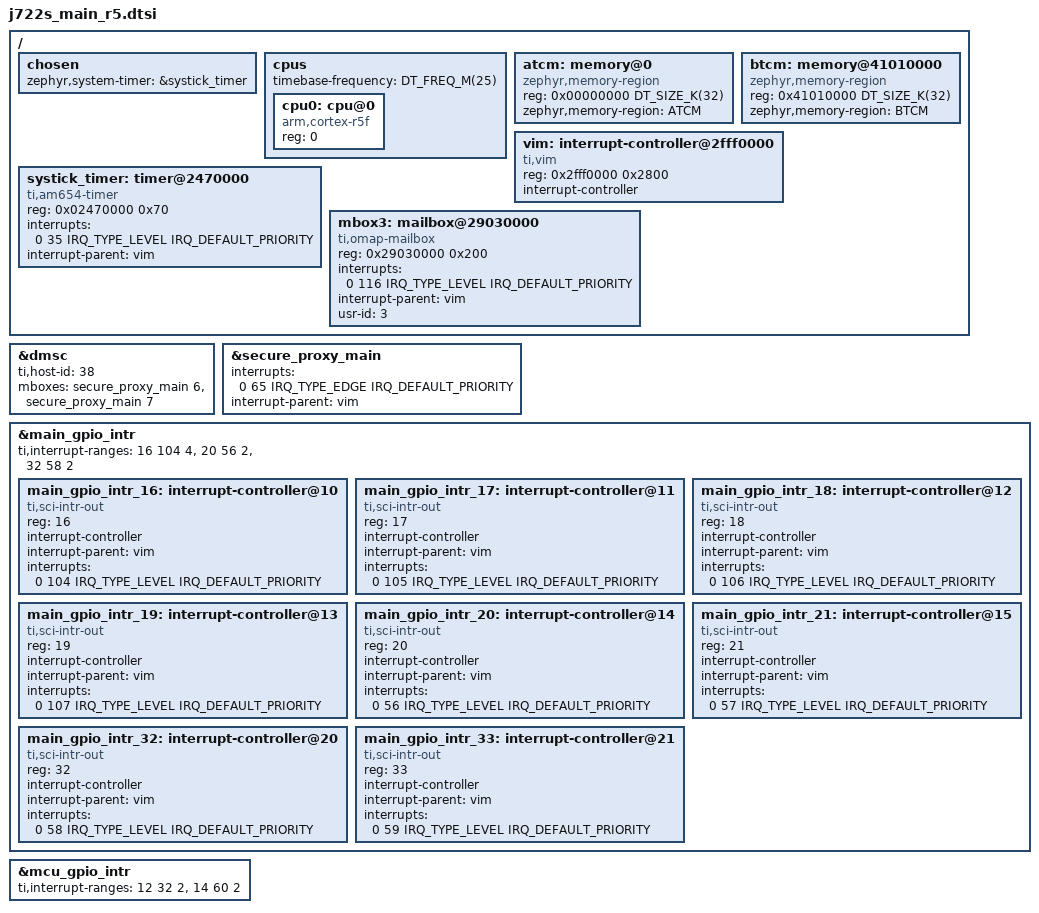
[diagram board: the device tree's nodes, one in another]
/*
 * Copyright (c) 2024 Texas Instruments Incorporated
 *	Andrew Davis <afd@ti.com>
 *
 * SPDX-License-Identifier: Apache-2.0
 */

#include <mem.h>
#include <freq.h>
#include <arm/armv7-r.dtsi>
#include <zephyr/dt-bindings/interrupt-controller/ti-vim.h>

#include "j722s_mcu.dtsi"
#include "j722s_main.dtsi"

/ {
	#address-cells = <1>;
	#size-cells = <1>;

	chosen {
		zephyr,system-timer = &systick_timer;
	};

	cpus {
		#address-cells = <1>;
		#size-cells = <0>;
		timebase-frequency = <DT_FREQ_M(25)>;

		cpu0: cpu@0 {
			device_type = "cpu";
			compatible = "arm,cortex-r5f";
			reg = <0>;
		};
	};

	atcm: memory@0 {
		device_type = "memory";
		compatible = "zephyr,memory-region", "mmio-sram";
		reg = <0x00000000 DT_SIZE_K(32)>;
		zephyr,memory-region = "ATCM";
	};

	btcm: memory@41010000 {
		device_type = "memory";
		compatible = "zephyr,memory-region", "mmio-sram";
		reg = <0x41010000 DT_SIZE_K(32)>;
		zephyr,memory-region = "BTCM";
	};

	vim: interrupt-controller@2fff0000 {
		#address-cells = <1>;
		compatible = "ti,vim";
		reg = <0x2fff0000 0x2800>;
		interrupt-controller;
		#interrupt-cells = <4>; /* {IRQ/FIQ, IRQ_NUM, IRQ_TYPE, IRQ_PRIO} */
		status = "okay";
	};

	systick_timer: timer@2470000 {
		compatible = "ti,am654-timer";
		reg = <0x02470000 0x70>;
		interrupts = <0 35 IRQ_TYPE_LEVEL IRQ_DEFAULT_PRIORITY>;
		interrupt-parent = <&vim>;
		status = "okay";
	};

	mbox3: mailbox@29030000 {
		compatible = "ti,omap-mailbox";
		reg = <0x29030000 0x200>;
		interrupts = <0 116 IRQ_TYPE_LEVEL IRQ_DEFAULT_PRIORITY>;
		interrupt-parent = <&vim>;
		usr-id = <3>;
		#mbox-cells = <1>;
		status = "okay";
	};
};

/* MAIN_0_R5_1 (non-secure): host 38, secure-proxy threads 6/7 */
&dmsc {
	ti,host-id = <38>;
	mboxes = <&secure_proxy_main 6>, <&secure_proxy_main 7>;
};

&secure_proxy_main {
	interrupt-names = "rx_6";
	interrupts = <0 65 IRQ_TYPE_EDGE IRQ_DEFAULT_PRIORITY>;
	interrupt-parent = <&vim>;
};

/*
 * MAIN GPIOMUX INTROUTER outputs wired to MAIN R5F VIM:
 *   out 16..19 -> VIM 104..107
 *   out 20..21 -> VIM 56..57
 *   out 32..33 -> VIM 58..59
 *
 * Each output is a ti,sci-intr-out child so peripherals can use
 * interrupt-parent = <&main_gpio_intr_N> with IR input in interrupts.
 * NUM_2ND_LEVEL_AGGREGATORS is capped at 8, matching these eight outputs.
 */
&main_gpio_intr {
	ti,interrupt-ranges = <16 104 4>,
			      <20 56 2>,
			      <32 58 2>;

	main_gpio_intr_16: interrupt-controller@10 {
		compatible = "ti,sci-intr-out";
		reg = <16>;
		interrupt-controller;
		#interrupt-cells = <2>;
		interrupt-parent = <&vim>;
		interrupts = <0 104 IRQ_TYPE_LEVEL IRQ_DEFAULT_PRIORITY>;
	};

	main_gpio_intr_17: interrupt-controller@11 {
		compatible = "ti,sci-intr-out";
		reg = <17>;
		interrupt-controller;
		#interrupt-cells = <2>;
		interrupt-parent = <&vim>;
		interrupts = <0 105 IRQ_TYPE_LEVEL IRQ_DEFAULT_PRIORITY>;
	};

	main_gpio_intr_18: interrupt-controller@12 {
		compatible = "ti,sci-intr-out";
		reg = <18>;
		interrupt-controller;
		#interrupt-cells = <2>;
		interrupt-parent = <&vim>;
		interrupts = <0 106 IRQ_TYPE_LEVEL IRQ_DEFAULT_PRIORITY>;
	};

	main_gpio_intr_19: interrupt-controller@13 {
		compatible = "ti,sci-intr-out";
		reg = <19>;
		interrupt-controller;
		#interrupt-cells = <2>;
		interrupt-parent = <&vim>;
		interrupts = <0 107 IRQ_TYPE_LEVEL IRQ_DEFAULT_PRIORITY>;
	};

	main_gpio_intr_20: interrupt-controller@14 {
		compatible = "ti,sci-intr-out";
		reg = <20>;
		interrupt-controller;
		#interrupt-cells = <2>;
		interrupt-parent = <&vim>;
		interrupts = <0 56 IRQ_TYPE_LEVEL IRQ_DEFAULT_PRIORITY>;
	};

	main_gpio_intr_21: interrupt-controller@15 {
		compatible = "ti,sci-intr-out";
		reg = <21>;
		interrupt-controller;
		#interrupt-cells = <2>;
		interrupt-parent = <&vim>;
		interrupts = <0 57 IRQ_TYPE_LEVEL IRQ_DEFAULT_PRIORITY>;
	};

	main_gpio_intr_32: interrupt-controller@20 {
		compatible = "ti,sci-intr-out";
		reg = <32>;
		interrupt-controller;
		#interrupt-cells = <2>;
		interrupt-parent = <&vim>;
		interrupts = <0 58 IRQ_TYPE_LEVEL IRQ_DEFAULT_PRIORITY>;
	};

	main_gpio_intr_33: interrupt-controller@21 {
		compatible = "ti,sci-intr-out";
		reg = <33>;
		interrupt-controller;
		#interrupt-cells = <2>;
		interrupt-parent = <&vim>;
		interrupts = <0 59 IRQ_TYPE_LEVEL IRQ_DEFAULT_PRIORITY>;
	};
};

/*
 * WKUP_MCU GPIOMUX INTROUTER outputs wired to MAIN R5F VIM:
 *   out 12..13 -> VIM 32..33
 *   out 14..15 -> VIM 60..61
 */
&mcu_gpio_intr {
	ti,interrupt-ranges = <12 32 2>,
			      <14 60 2>;
};
